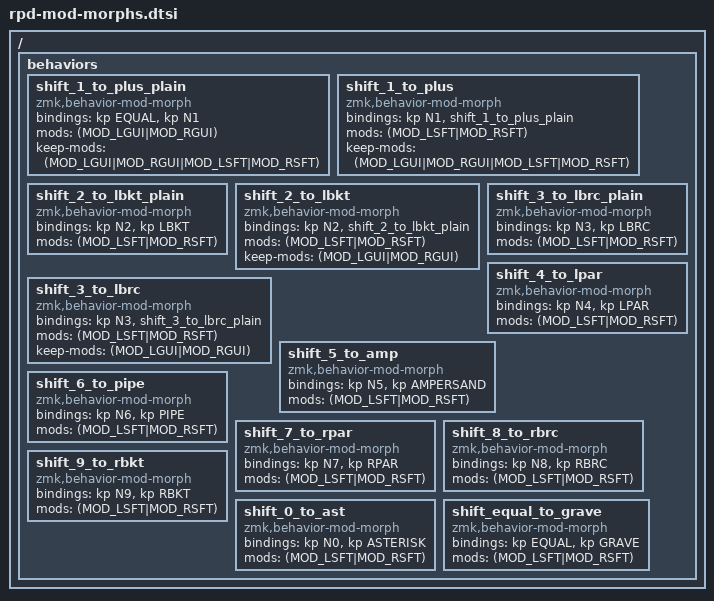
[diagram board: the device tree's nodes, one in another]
/ {
    behaviors {
        shift_1_to_plus_plain: shift_1_to_plus_plain {
            compatible = "zmk,behavior-mod-morph";
            #binding-cells = <0>;
            bindings = <&kp EQUAL>, <&kp N1>;
            mods = <(MOD_LGUI|MOD_RGUI)>;
            keep-mods = <(MOD_LGUI|MOD_RGUI|MOD_LSFT|MOD_RSFT)>;
        };
        
        shift_1_to_plus: shift_1_to_plus {
            compatible = "zmk,behavior-mod-morph";
            #binding-cells = <0>;
            bindings = <&kp N1>, <&shift_1_to_plus_plain>;
            mods = <(MOD_LSFT|MOD_RSFT)>;
            keep-mods = <(MOD_LGUI|MOD_RGUI|MOD_LSFT|MOD_RSFT)>;
        };

        shift_2_to_lbkt_plain: shift_2_to_lbkt_plain {
            compatible = "zmk,behavior-mod-morph";
            #binding-cells = <0>;
            bindings = <&kp N2>, <&kp LBKT>;
            mods = <(MOD_LSFT|MOD_RSFT)>;
        };

        shift_2_to_lbkt: shift_2_to_lbkt {
            compatible = "zmk,behavior-mod-morph";
            #binding-cells = <0>;
            bindings = <&kp N2>, <&shift_2_to_lbkt_plain>;
            mods = <(MOD_LSFT|MOD_RSFT)>;
            keep-mods = <(MOD_LGUI|MOD_RGUI)>;
        };

        shift_3_to_lbrc_plain: shift_3_to_lbrc_plain {
            compatible = "zmk,behavior-mod-morph";
            #binding-cells = <0>;
            bindings = <&kp N3>, <&kp LBRC>;
            mods = <(MOD_LSFT|MOD_RSFT)>;
        };

        shift_3_to_lbrc: shift_3_to_lbrc {
            compatible = "zmk,behavior-mod-morph";
            #binding-cells = <0>;
            bindings = <&kp N3>, <&shift_3_to_lbrc_plain>;
            mods = <(MOD_LSFT|MOD_RSFT)>;
            keep-mods = <(MOD_LGUI|MOD_RGUI)>;
        };

        shift_4_to_lpar: shift_4_to_lpar {
            compatible = "zmk,behavior-mod-morph";
            #binding-cells = <0>;
            bindings = <&kp N4>, <&kp LPAR>;
            mods = <(MOD_LSFT|MOD_RSFT)>;
        };

        shift_5_to_amp: shift_5_to_amp {
            compatible = "zmk,behavior-mod-morph";
            #binding-cells = <0>;
            bindings = <&kp N5>, <&kp AMPERSAND>;
            mods = <(MOD_LSFT|MOD_RSFT)>;
        };

        shift_6_to_pipe: shift_6_to_pipe {
            compatible = "zmk,behavior-mod-morph";
            #binding-cells = <0>;
            bindings = <&kp N6>, <&kp PIPE>;
            mods = <(MOD_LSFT|MOD_RSFT)>;
        };

        shift_7_to_rpar: shift_7_to_rpar {
            compatible = "zmk,behavior-mod-morph";
            #binding-cells = <0>;
            bindings = <&kp N7>, <&kp RPAR>;
            mods = <(MOD_LSFT|MOD_RSFT)>;
        };

        shift_8_to_rbrc: shift_8_to_rbrc {
            compatible = "zmk,behavior-mod-morph";
            #binding-cells = <0>;
            bindings = <&kp N8>, <&kp RBRC>;
            mods = <(MOD_LSFT|MOD_RSFT)>;
        };

        shift_9_to_rbkt: shift_9_to_rbkt {
            compatible = "zmk,behavior-mod-morph";
            #binding-cells = <0>;
            bindings = <&kp N9>, <&kp RBKT>;
            mods = <(MOD_LSFT|MOD_RSFT)>;
        };

        shift_0_to_ast: shift_0_to_ast {
            compatible = "zmk,behavior-mod-morph";
            #binding-cells = <0>;
            bindings = <&kp N0>, <&kp ASTERISK>;
            mods = <(MOD_LSFT|MOD_RSFT)>;
        };

        shift_equal_to_grave: shift_equal_to_grave {
            compatible = "zmk,behavior-mod-morph";
            #binding-cells = <0>;
            bindings = <&kp EQUAL>, <&kp GRAVE>;
            mods = <(MOD_LSFT|MOD_RSFT)>;
        };
    };
};
